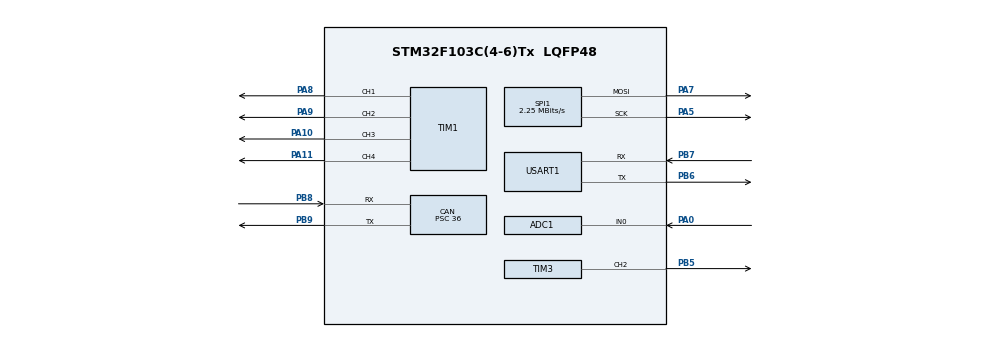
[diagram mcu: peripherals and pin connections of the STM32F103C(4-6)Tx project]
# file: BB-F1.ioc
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ADC1.Channel-0\#ChannelRegularConversion=ADC_CHANNEL_VREFINT
ADC1.NbrOfConversionFlag=1
ADC1.Rank-0\#ChannelRegularConversion=1
ADC1.SamplingTime-0\#ChannelRegularConversion=ADC_SAMPLETIME_1CYCLE_5
ADC1.master=1
CAN.BS1=CAN_BS1_4TQ
CAN.BS2=CAN_BS2_5TQ
CAN.CalculateBaudRate=100000
CAN.CalculateTimeBit=10000
CAN.CalculateTimeQuantum=1000.0
CAN.Prescaler=36
CAN.SJW=CAN_SJW_1TQ
Dma.Request0=SPI1_TX
Dma.SPI1_TX.0.Direction=DMA_MEMORY_TO_PERIPH
Dma.SPI1_TX.0.Instance=DMA1_Channel3
Dma.SPI1_TX.0.MemDataAlignment=DMA_MDATAALIGN_BYTE
Dma.SPI1_TX.0.MemInc=DMA_MINC_ENABLE
Dma.SPI1_TX.0.Mode=DMA_NORMAL
Dma.SPI1_TX.0.PeriphDataAlignment=DMA_PDATAALIGN_BYTE
Dma.SPI1_TX.0.PeriphInc=DMA_PINC_DISABLE
Dma.SPI1_TX.0.Priority=DMA_PRIORITY_LOW
Mcu.Family=STM32F1
Mcu.Name=STM32F103C(4-6)Tx
Mcu.Package=LQFP48
NVIC.CAN1_RX1_IRQn=true\:0\:0\:false\:false\:false\:true\:true\:true
NVIC.DMA1_Channel3_IRQn=true\:0\:0\:false\:false\:false\:false\:true\:true
NVIC.PriorityGroup=NVIC_PRIORITYGROUP_4
NVIC.SPI1_IRQn=true\:0\:0\:false\:false\:false\:true\:true\:true
NVIC.TIM3_IRQn=true\:0\:0\:false\:false\:false\:true\:true\:true
NVIC.USB_LP_CAN1_RX0_IRQn=true\:0\:0\:false\:false\:false\:true\:true\:true
PA0-WKUP.Signal=ADCx_IN0
PA10.Signal=S_TIM1_CH3
PA11.Signal=S_TIM1_CH4
PA5.Mode=TX_Only_Simplex_Unidirect_Master
PA5.Signal=SPI1_SCK
PA7.Mode=TX_Only_Simplex_Unidirect_Master
PA7.Signal=SPI1_MOSI
PA8.Signal=S_TIM1_CH1
PA9.Signal=S_TIM1_CH2
PB5.Signal=S_TIM3_CH2
PB6.Mode=Asynchronous
PB6.Signal=USART1_TX
PB7.Mode=Asynchronous
PB7.Signal=USART1_RX
PB8.Mode=CAN_Activate
PB8.Signal=CAN_RX
PB9.Mode=CAN_Activate
PB9.Signal=CAN_TX
PD0-OSC_IN.Mode=HSE-External-Oscillator
PD0-OSC_IN.Signal=RCC_OSC_IN
PD1-OSC_OUT.Mode=HSE-External-Oscillator
PD1-OSC_OUT.Signal=RCC_OSC_OUT
ProjectManager.HeapSize=0x200
ProjectManager.StackSize=0x400
ProjectManager.TargetToolchain=MDK-ARM V5.32
RCC.ADCPresc=RCC_ADCPCLK2_DIV6
RCC.AHBFreq_Value=72000000
RCC.APB1CLKDivider=RCC_HCLK_DIV2
RCC.APB1Freq_Value=36000000
RCC.APB1TimFreq_Value=72000000
RCC.APB2Freq_Value=72000000
RCC.APB2TimFreq_Value=72000000
RCC.HCLKFreq_Value=72000000
RCC.PLLMUL=RCC_PLL_MUL9
RCC.PLLSourceVirtual=RCC_PLLSOURCE_HSE
RCC.SYSCLKFreq_VALUE=72000000
RCC.SYSCLKSource=RCC_SYSCLKSOURCE_PLLCLK
RCC.USBFreq_Value=72000000
SH.ADCx_IN0.0=ADC1_IN0,IN0
SH.S_TIM1_CH1.0=TIM1_CH1,PWM Generation1 CH1
SH.S_TIM1_CH2.0=TIM1_CH2,PWM Generation2 CH2
SH.S_TIM1_CH3.0=TIM1_CH3,PWM Generation3 CH3
SH.S_TIM1_CH4.0=TIM1_CH4,PWM Generation4 CH4
SH.S_TIM3_CH2.0=TIM3_CH2,PWM Generation2 CH2
SPI1.BaudRatePrescaler=SPI_BAUDRATEPRESCALER_32
SPI1.CalculateBaudRate=2.25 MBits/s
SPI1.Direction=SPI_DIRECTION_2LINES
SPI1.Mode=SPI_MODE_MASTER
SPI1.VirtualType=VM_MASTER
TIM1.Channel-PWM\ Generation1\ CH1=TIM_CHANNEL_1
TIM1.Channel-PWM\ Generation2\ CH2=TIM_CHANNEL_2
TIM1.Channel-PWM\ Generation3\ CH3=TIM_CHANNEL_3
TIM1.Channel-PWM\ Generation4\ CH4=TIM_CHANNEL_4
TIM3.Channel-PWM\ Generation2\ CH2=TIM_CHANNEL_2
TIM3.Period=999
TIM3.Prescaler=71
USART1.VirtualMode=VM_ASYNC
VP_ADC1_Vref_Input.Mode=IN-Vrefint
VP_SYS_VS_ND.Mode=No_Debug
VP_TIM1_VS_ClockSourceINT.Mode=Internal
VP_TIM2_VS_ClockSourceINT.Mode=Internal
VP_TIM3_VS_ClockSourceINT.Mode=Internal
board=custom

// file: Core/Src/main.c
/* USER CODE BEGIN Header */
/**
  ******************************************************************************
  * @file           : main.c
  * @brief          : Main program body
  ******************************************************************************
  * @attention
  *
  * Copyright (c) 2023 STMicroelectronics.
  * All rights reserved.
  *
  * This software is licensed under terms that can be found in the LICENSE file
  * in the root directory of this software component.
  * If no LICENSE file comes with this software, it is provided AS-IS.
  *
  ******************************************************************************
  */
/* USER CODE END Header */
#include "main.h"
#include "adc.h"
#include "can.h"
#include "dma.h"
#include "spi.h"
#include "tim.h"
#include "usart.h"
#include "gpio.h"

/* USER CODE BEGIN Includes */
#include "Task.h"
/* USER CODE END Includes */

/* USER CODE BEGIN PV */
extern void initTask(void);
/* USER CODE END PV */

void SystemClock_Config(void);

int main(void)
{

  /* MCU Configuration--------------------------------------------------------*/

  /* Reset of all peripherals, Initializes the Flash interface and the Systick. */
  HAL_Init();

  /* Configure the system clock */
  SystemClock_Config();

  /* Initialize all configured peripherals */
  MX_GPIO_Init();
  MX_DMA_Init();
  MX_ADC1_Init();
  MX_CAN_Init();
  MX_SPI1_Init();
  MX_TIM1_Init();
  MX_TIM2_Init();
  MX_TIM3_Init();
  MX_USART1_UART_Init();
  /* USER CODE BEGIN 2 */
  void initTask(void);
  /* USER CODE END 2 */

  /* Infinite loop */
  while (1)
  {

  }
}

void SystemClock_Config(void)
{
  LL_FLASH_SetLatency(LL_FLASH_LATENCY_2);
  while(LL_FLASH_GetLatency()!= LL_FLASH_LATENCY_2)
  {
  }
  LL_RCC_HSE_Enable();

   /* Wait till HSE is ready */
  while(LL_RCC_HSE_IsReady() != 1)
  {

  }
  LL_RCC_PLL_ConfigDomain_SYS(LL_RCC_PLLSOURCE_HSE_DIV_1, LL_RCC_PLL_MUL_9);
  LL_RCC_PLL_Enable();

   /* Wait till PLL is ready */
  while(LL_RCC_PLL_IsReady() != 1)
  {

  }
  LL_RCC_SetAHBPrescaler(LL_RCC_SYSCLK_DIV_1);
  LL_RCC_SetAPB1Prescaler(LL_RCC_APB1_DIV_2);
  LL_RCC_SetAPB2Prescaler(LL_RCC_APB2_DIV_1);
  LL_RCC_SetSysClkSource(LL_RCC_SYS_CLKSOURCE_PLL);

   /* Wait till System clock is ready */
  while(LL_RCC_GetSysClkSource() != LL_RCC_SYS_CLKSOURCE_STATUS_PLL)
  {

  }
  LL_SetSystemCoreClock(72000000);

   /* Update the time base */
  if (HAL_InitTick (TICK_INT_PRIORITY) != HAL_OK)
  {
    Error_Handler();
  }
  LL_RCC_SetADCClockSource(LL_RCC_ADC_CLKSRC_PCLK2_DIV_6);
}

void Error_Handler(void)
{
  __disable_irq();
  while (1)
  {
  }
}
